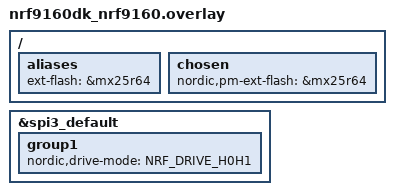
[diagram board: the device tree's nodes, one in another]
/* Enable high drive mode for the SPI3 pins to get a square signal at 8 MHz */
&spi3_default {
	group1 {
		nordic,drive-mode = <NRF_DRIVE_H0H1>;
	};
};

/ {
	aliases {
		ext-flash = &mx25r64;
	};

	chosen {
		nordic,pm-ext-flash = &mx25r64;
	};
};
